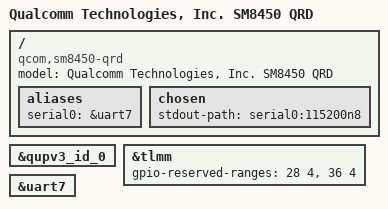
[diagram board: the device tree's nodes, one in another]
// SPDX-License-Identifier: BSD-3-Clause
/*
 * Copyright (c) 2021, Linaro Limited
 */

/dts-v1/;

#include "sm8450.dtsi"

/ {
	model = "Qualcomm Technologies, Inc. SM8450 QRD";
	compatible = "qcom,sm8450-qrd", "qcom,sm8450";

	aliases {
		serial0 = &uart7;
	};

	chosen {
		stdout-path = "serial0:115200n8";
	};
};

&qupv3_id_0 {
	status = "okay";
};

&tlmm {
	gpio-reserved-ranges = <28 4>, <36 4>;
};

&uart7 {
	status = "okay";
};
